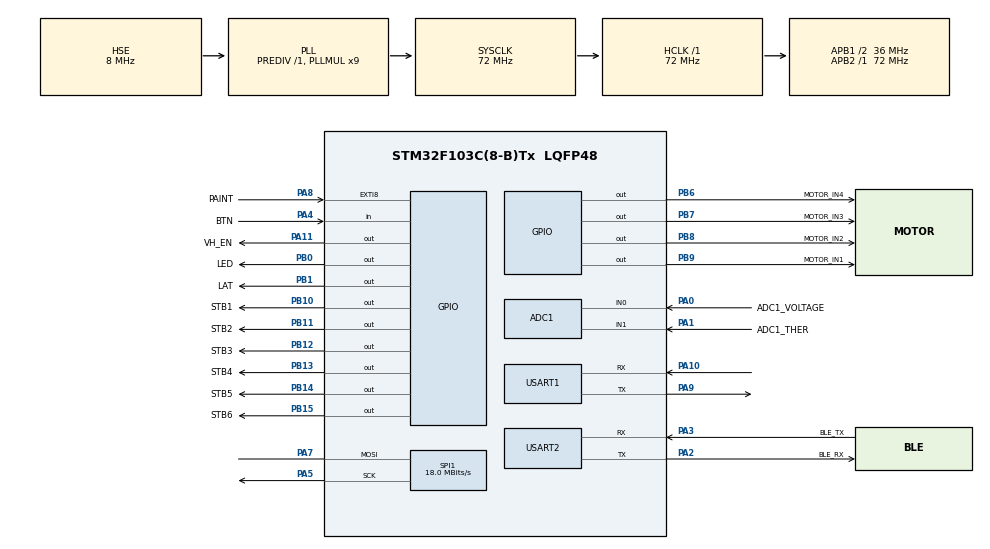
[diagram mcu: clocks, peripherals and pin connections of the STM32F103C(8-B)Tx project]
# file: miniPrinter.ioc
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ADC1.Channel-1\#ChannelRegularConversion=ADC_CHANNEL_0
ADC1.Channel-2\#ChannelRegularConversion=ADC_CHANNEL_1
ADC1.Channel-4\#ChannelRegularConversion=ADC_CHANNEL_VREFINT
ADC1.ContinuousConvMode=ENABLE
ADC1.DiscontinuousConvMode=DISABLE
ADC1.NbrOfConversion=3
ADC1.NbrOfConversionFlag=1
ADC1.Rank-1\#ChannelRegularConversion=1
ADC1.Rank-2\#ChannelRegularConversion=2
ADC1.Rank-4\#ChannelRegularConversion=3
ADC1.SamplingTime-1\#ChannelRegularConversion=ADC_SAMPLETIME_239CYCLES_5
ADC1.SamplingTime-2\#ChannelRegularConversion=ADC_SAMPLETIME_239CYCLES_5
ADC1.SamplingTime-4\#ChannelRegularConversion=ADC_SAMPLETIME_71CYCLES_5
ADC1.master=1
Dma.ADC1.0.Direction=DMA_PERIPH_TO_MEMORY
Dma.ADC1.0.Instance=DMA1_Channel1
Dma.ADC1.0.MemDataAlignment=DMA_MDATAALIGN_HALFWORD
Dma.ADC1.0.MemInc=DMA_MINC_ENABLE
Dma.ADC1.0.Mode=DMA_CIRCULAR
Dma.ADC1.0.PeriphDataAlignment=DMA_PDATAALIGN_HALFWORD
Dma.ADC1.0.PeriphInc=DMA_PINC_DISABLE
Dma.ADC1.0.Priority=DMA_PRIORITY_LOW
Dma.Request0=ADC1
FREERTOS.Tasks01=defaultTask,0,128,StartDefaultTask,Default,NULL,Dynamic,NULL,NULL
FREERTOS.configTOTAL_HEAP_SIZE=4072
FREERTOS.configUSE_TIMERS=1
Mcu.Family=STM32F1
Mcu.Name=STM32F103C(8-B)Tx
Mcu.Package=LQFP48
NVIC.DMA1_Channel1_IRQn=true\:5\:0\:false\:false\:true\:true\:false\:true\:true
NVIC.EXTI9_5_IRQn=true\:5\:0\:true\:false\:true\:true\:true\:true\:true
NVIC.PriorityGroup=NVIC_PRIORITYGROUP_4
NVIC.TIM4_IRQn=true\:15\:0\:false\:false\:true\:false\:false\:true\:true
NVIC.TimeBase=TIM4_IRQn
NVIC.TimeBaseIP=TIM4
NVIC.USART2_IRQn=true\:5\:0\:false\:false\:true\:true\:true\:true\:true
PA0-WKUP.GPIO_Label=ADC1_VOLTAGE
PA0-WKUP.Signal=ADCx_IN0
PA1.GPIO_Label=ADC1_THER
PA1.Signal=ADCx_IN1
PA10.Mode=Asynchronous
PA10.Signal=USART1_RX
PA11.GPIO_Label=VH_EN
PA11.Signal=GPIO_Output
PA13.Mode=Serial_Wire
PA13.Signal=SYS_JTMS-SWDIO
PA14.Mode=Serial_Wire
PA14.Signal=SYS_JTCK-SWCLK
PA2.GPIO_Label=BLE_RX
PA2.Mode=Asynchronous
PA2.Signal=USART2_TX
PA3.GPIO_Label=BLE_TX
PA3.Mode=Asynchronous
PA3.Signal=USART2_RX
PA4.GPIO_Label=BTN
PA4.Signal=GPIO_Input
PA5.Mode=Simplex_Bidirectional_Master
PA5.Signal=SPI1_SCK
PA7.Mode=Simplex_Bidirectional_Master
PA7.Signal=SPI1_MOSI
PA8.GPIO_Label=PAINT
PA8.Signal=GPXTI8
PA9.Mode=Asynchronous
PA9.Signal=USART1_TX
PB0.GPIO_Label=LED
PB0.PinState=GPIO_PIN_SET
PB0.Signal=GPIO_Output
PB1.GPIO_Label=LAT
PB1.GPIO_PuPd=GPIO_PULLUP
PB1.PinState=GPIO_PIN_SET
PB1.Signal=GPIO_Output
PB10.GPIO_Label=STB1
PB10.Signal=GPIO_Output
PB11.GPIO_Label=STB2
PB11.Signal=GPIO_Output
PB12.GPIO_Label=STB3
PB12.Signal=GPIO_Output
PB13.GPIO_Label=STB4
PB13.Signal=GPIO_Output
PB14.GPIO_Label=STB5
PB14.Signal=GPIO_Output
PB15.GPIO_Label=STB6
PB15.Signal=GPIO_Output
PB6.GPIO_Label=MOTOR_IN4
PB6.Signal=GPIO_Output
PB7.GPIO_Label=MOTOR_IN3
PB7.Signal=GPIO_Output
PB8.GPIO_Label=MOTOR_IN2
PB8.Signal=GPIO_Output
PB9.GPIO_Label=MOTOR_IN1
PB9.Signal=GPIO_Output
PD0-OSC_IN.Mode=HSE-External-Oscillator
PD0-OSC_IN.Signal=RCC_OSC_IN
PD1-OSC_OUT.Mode=HSE-External-Oscillator
PD1-OSC_OUT.Signal=RCC_OSC_OUT
ProjectManager.HeapSize=0x200
ProjectManager.StackSize=0x400
ProjectManager.TargetToolchain=CMake
RCC.ADCPresc=RCC_ADCPCLK2_DIV6
RCC.AHBFreq_Value=72000000
RCC.APB1CLKDivider=RCC_HCLK_DIV2
RCC.APB1Freq_Value=36000000
RCC.APB1TimFreq_Value=72000000
RCC.APB2Freq_Value=72000000
RCC.APB2TimFreq_Value=72000000
RCC.HCLKFreq_Value=72000000
RCC.PLLMUL=RCC_PLL_MUL9
RCC.PLLSourceVirtual=RCC_PLLSOURCE_HSE
RCC.SYSCLKFreq_VALUE=72000000
RCC.SYSCLKSource=RCC_SYSCLKSOURCE_PLLCLK
RCC.USBFreq_Value=72000000
SH.ADCx_IN0.0=ADC1_IN0,IN0
SH.ADCx_IN1.0=ADC1_IN1,IN1
SPI1.BaudRatePrescaler=SPI_BAUDRATEPRESCALER_4
SPI1.CalculateBaudRate=18.0 MBits/s
SPI1.Direction=SPI_DIRECTION_1LINE
SPI1.Mode=SPI_MODE_MASTER
SPI1.VirtualType=VM_MASTER
TIM1.Prescaler=71
USART1.VirtualMode=VM_ASYNC
USART2.VirtualMode=VM_ASYNC
VP_ADC1_Vref_Input.Mode=IN-Vrefint
VP_FREERTOS_VS_CMSIS_V1.Mode=CMSIS_V1
VP_SYS_VS_tim4.Mode=TIM4
VP_TIM1_VS_ClockSourceINT.Mode=Internal
board=custom

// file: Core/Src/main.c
/* USER CODE BEGIN Header */
/**
  ******************************************************************************
  * @file           : main.c
  * @brief          : Main program body
  ******************************************************************************
  * @attention
  *
  * Copyright (c) 2025 STMicroelectronics.
  * All rights reserved.
  *
  * This software is licensed under terms that can be found in the LICENSE file
  * in the root directory of this software component.
  * If no LICENSE file comes with this software, it is provided AS-IS.
  *
  ******************************************************************************
  */
/* USER CODE END Header */
#include "main.h"
#include "cmsis_os.h"
#include "adc.h"
#include "dma.h"
#include "spi.h"
#include "tim.h"
#include "usart.h"
#include "gpio.h"

/* USER CODE BEGIN Includes */
#include "common.h"
/* USER CODE END Includes */

/* USER CODE BEGIN PTD */
#include "dr_ble.h"
#include "test.h"
#include "timers.h"
/* USER CODE END PTD */

void SystemClock_Config(void);
void MX_FREERTOS_Init(void);

/* USER CODE BEGIN 0 */
extern uint8_t aRxBuffer;
/* USER CODE END 0 */

int main(void)
{

  /* MCU Configuration--------------------------------------------------------*/

  /* Reset of all peripherals, Initializes the Flash interface and the Systick. */
  HAL_Init();

  /* Configure the system clock */
  SystemClock_Config();

  /* Initialize all configured peripherals */
  MX_GPIO_Init();
  MX_DMA_Init();
  MX_USART1_UART_Init();
  MX_ADC1_Init();
  MX_TIM1_Init();
  MX_USART2_UART_Init();
  MX_SPI1_Init();
  /* USER CODE BEGIN 2 */
  HAL_UART_Receive_IT(&huart2, (uint8_t *)&aRxBuffer, 1);
  init_task();
  /* USER CODE END 2 */

  /* Call init function for freertos objects (in cmsis_os2.c) */
  MX_FREERTOS_Init();

  /* Start scheduler */
  osKernelStart();

  /* We should never get here as control is now taken by the scheduler */

  /* Infinite loop */
  /* USER CODE BEGIN WHILE */
  while (1)
  {
    // // printf("vol =  %.2f\n", get_adc_volts());
    // read_all_hal();
    // HAL_Delay(100);

    /* USER CODE END WHILE */

  }
}

void SystemClock_Config(void)
{
  RCC_OscInitTypeDef RCC_OscInitStruct = {0};
  RCC_ClkInitTypeDef RCC_ClkInitStruct = {0};
  RCC_PeriphCLKInitTypeDef PeriphClkInit = {0};

  /** Initializes the RCC Oscillators according to the specified parameters
  * in the RCC_OscInitTypeDef structure.
  */
  RCC_OscInitStruct.OscillatorType = RCC_OSCILLATORTYPE_HSE;
  RCC_OscInitStruct.HSEState = RCC_HSE_ON;
  RCC_OscInitStruct.HSEPredivValue = RCC_HSE_PREDIV_DIV1;
  RCC_OscInitStruct.HSIState = RCC_HSI_ON;
  RCC_OscInitStruct.PLL.PLLState = RCC_PLL_ON;
  RCC_OscInitStruct.PLL.PLLSource = RCC_PLLSOURCE_HSE;
  RCC_OscInitStruct.PLL.PLLMUL = RCC_PLL_MUL9;
  if (HAL_RCC_OscConfig(&RCC_OscInitStruct) != HAL_OK)
  {
    Error_Handler();
  }

  /** Initializes the CPU, AHB and APB buses clocks
  */
  RCC_ClkInitStruct.ClockType = RCC_CLOCKTYPE_HCLK|RCC_CLOCKTYPE_SYSCLK
                              |RCC_CLOCKTYPE_PCLK1|RCC_CLOCKTYPE_PCLK2;
  RCC_ClkInitStruct.SYSCLKSource = RCC_SYSCLKSOURCE_PLLCLK;
  RCC_ClkInitStruct.AHBCLKDivider = RCC_SYSCLK_DIV1;
  RCC_ClkInitStruct.APB1CLKDivider = RCC_HCLK_DIV2;
  RCC_ClkInitStruct.APB2CLKDivider = RCC_HCLK_DIV1;

  if (HAL_RCC_ClockConfig(&RCC_ClkInitStruct, FLASH_LATENCY_2) != HAL_OK)
  {
    Error_Handler();
  }
  PeriphClkInit.PeriphClockSelection = RCC_PERIPHCLK_ADC;
  PeriphClkInit.AdcClockSelection = RCC_ADCPCLK2_DIV6;
  if (HAL_RCCEx_PeriphCLKConfig(&PeriphClkInit) != HAL_OK)
  {
    Error_Handler();
  }
}

void HAL_TIM_PeriodElapsedCallback(TIM_HandleTypeDef *htim)
{
  if (htim->Instance == TIM4)
  {
    HAL_IncTick();
  }
}

void Error_Handler(void)
{
  __disable_irq();
  while (1)
  {
  }
}

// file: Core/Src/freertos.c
/* USER CODE BEGIN Header */
/**
  ******************************************************************************
  * File Name          : freertos.c
  * Description        : Code for freertos applications
  ******************************************************************************
  * @attention
  *
  * Copyright (c) 2025 STMicroelectronics.
  * All rights reserved.
  *
  * This software is licensed under terms that can be found in the LICENSE file
  * in the root directory of this software component.
  * If no LICENSE file comes with this software, it is provided AS-IS.
  *
  ******************************************************************************
  */
/* USER CODE END Header */

#include "FreeRTOS.h"
#include "task.h"
#include "main.h"
#include "cmsis_os.h"

osThreadId defaultTaskHandle;

void StartDefaultTask(void const * argument);

void MX_FREERTOS_Init(void); /* (MISRA C 2004 rule 8.1) */

/* GetIdleTaskMemory prototype (linked to static allocation support) */
void vApplicationGetIdleTaskMemory( StaticTask_t **ppxIdleTaskTCBBuffer, StackType_t **ppxIdleTaskStackBuffer, uint32_t *pulIdleTaskStackSize );

/* GetTimerTaskMemory prototype (linked to static allocation support) */
void vApplicationGetTimerTaskMemory( StaticTask_t **ppxTimerTaskTCBBuffer, StackType_t **ppxTimerTaskStackBuffer, uint32_t *pulTimerTaskStackSize );

/* USER CODE BEGIN GET_IDLE_TASK_MEMORY */
static StaticTask_t xIdleTaskTCBBuffer;
static StackType_t xIdleStack[configMINIMAL_STACK_SIZE];

void vApplicationGetIdleTaskMemory( StaticTask_t **ppxIdleTaskTCBBuffer, StackType_t **ppxIdleTaskStackBuffer, uint32_t *pulIdleTaskStackSize )
{
  *ppxIdleTaskTCBBuffer = &xIdleTaskTCBBuffer;
  *ppxIdleTaskStackBuffer = &xIdleStack[0];
  *pulIdleTaskStackSize = configMINIMAL_STACK_SIZE;
  /* place for user code */
}
/* USER CODE END GET_IDLE_TASK_MEMORY */

/* USER CODE BEGIN GET_TIMER_TASK_MEMORY */
static StaticTask_t xTimerTaskTCBBuffer;
static StackType_t xTimerStack[configTIMER_TASK_STACK_DEPTH];

void vApplicationGetTimerTaskMemory( StaticTask_t **ppxTimerTaskTCBBuffer, StackType_t **ppxTimerTaskStackBuffer, uint32_t *pulTimerTaskStackSize )
{
  *ppxTimerTaskTCBBuffer = &xTimerTaskTCBBuffer;
  *ppxTimerTaskStackBuffer = &xTimerStack[0];
  *pulTimerTaskStackSize = configTIMER_TASK_STACK_DEPTH;
  /* place for user code */
}
/* USER CODE END GET_TIMER_TASK_MEMORY */

void MX_FREERTOS_Init(void) {

  /* Create the thread(s) */
  /* definition and creation of defaultTask */
  osThreadDef(defaultTask, StartDefaultTask, osPriorityNormal, 0, 128);
  defaultTaskHandle = osThreadCreate(osThread(defaultTask), NULL);

}

void StartDefaultTask(void const * argument)
{
  for(;;)
  {
    osDelay(1);
  }
}
